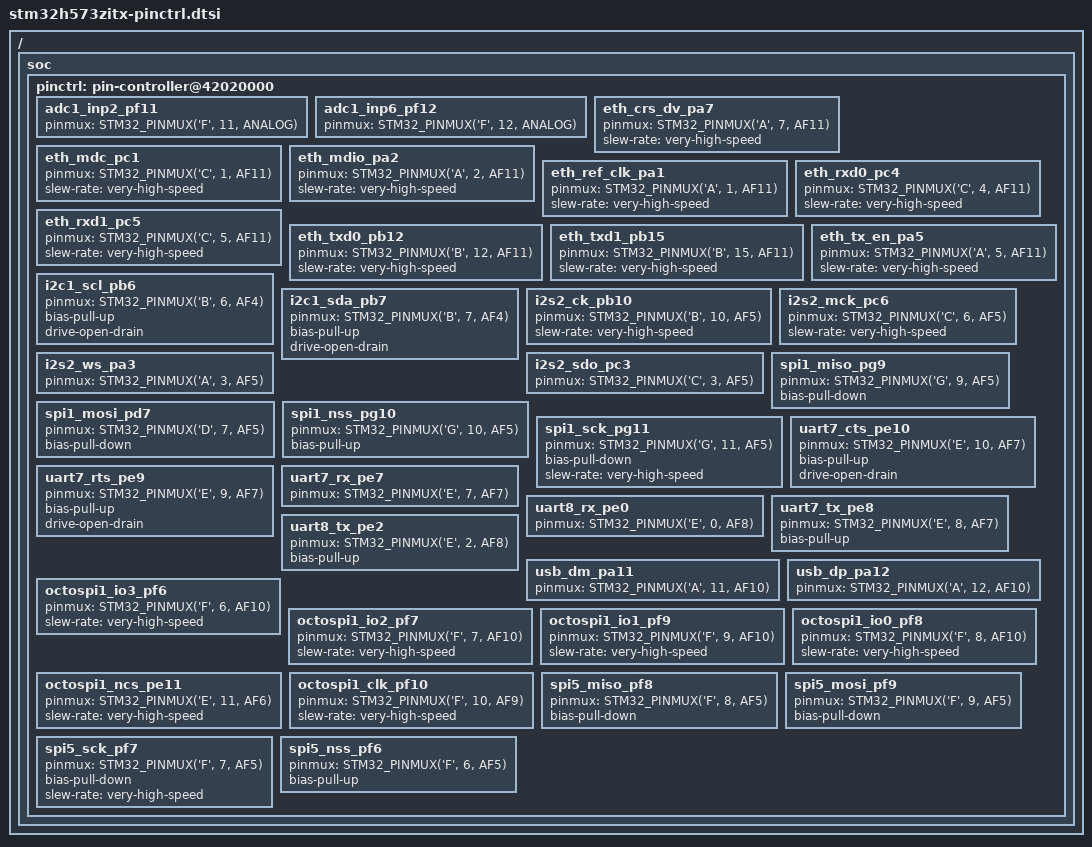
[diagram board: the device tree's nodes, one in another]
#include <zephyr/dt-bindings/pinctrl/stm32-pinctrl.h>

/ {
	soc {
		pinctrl: pin-controller@42020000 {

			/* ADC_IN / ADC_INN / ADC_INP */

			/omit-if-no-ref/ adc1_inp2_pf11: adc1_inp2_pf11 {
				pinmux = <STM32_PINMUX('F', 11, ANALOG)>;
			};

			/omit-if-no-ref/ adc1_inp6_pf12: adc1_inp6_pf12 {
				pinmux = <STM32_PINMUX('F', 12, ANALOG)>;
			};

			/* ETH_CRS_DV */

			/omit-if-no-ref/ eth_crs_dv_pa7: eth_crs_dv_pa7 {
				pinmux = <STM32_PINMUX('A', 7, AF11)>;
				slew-rate = "very-high-speed";
			};

			/* ETH_MDC */

			/omit-if-no-ref/ eth_mdc_pc1: eth_mdc_pc1 {
				pinmux = <STM32_PINMUX('C', 1, AF11)>;
				slew-rate = "very-high-speed";
			};

			/* ETH_MDIO */

			/omit-if-no-ref/ eth_mdio_pa2: eth_mdio_pa2 {
				pinmux = <STM32_PINMUX('A', 2, AF11)>;
				slew-rate = "very-high-speed";
			};


			/* ETH_REF_CLK */

			/omit-if-no-ref/ eth_ref_clk_pa1: eth_ref_clk_pa1 {
				pinmux = <STM32_PINMUX('A', 1, AF11)>;
				slew-rate = "very-high-speed";
			};

			/* ETH_RXD0 */

			/omit-if-no-ref/ eth_rxd0_pc4: eth_rxd0_pc4 {
				pinmux = <STM32_PINMUX('C', 4, AF11)>;
				slew-rate = "very-high-speed";
			};

			/* ETH_RXD1 */

			/omit-if-no-ref/ eth_rxd1_pc5: eth_rxd1_pc5 {
				pinmux = <STM32_PINMUX('C', 5, AF11)>;
				slew-rate = "very-high-speed";
			};

			/* ETH_TXD0 */

			/omit-if-no-ref/ eth_txd0_pb12: eth_txd0_pb12 {
				pinmux = <STM32_PINMUX('B', 12, AF11)>;
				slew-rate = "very-high-speed";
			};

			/* ETH_TXD1 */

			/omit-if-no-ref/ eth_txd1_pb15: eth_txd1_pb15 {
				pinmux = <STM32_PINMUX('B', 15, AF11)>;
				slew-rate = "very-high-speed";
			};

			/* ETH_TX_EN */

			/omit-if-no-ref/ eth_tx_en_pa5: eth_tx_en_pa5 {
				pinmux = <STM32_PINMUX('A', 5, AF11)>;
				slew-rate = "very-high-speed";
			};


			/* I2C_SCL */

			/omit-if-no-ref/ i2c1_scl_pb6: i2c1_scl_pb6 {
				pinmux = <STM32_PINMUX('B', 6, AF4)>;
				bias-pull-up;
				drive-open-drain;
			};

			/* I2C_SDA */

			/omit-if-no-ref/ i2c1_sda_pb7: i2c1_sda_pb7 {
				pinmux = <STM32_PINMUX('B', 7, AF4)>;
				bias-pull-up;
				drive-open-drain;
			};



			/* I2S_CK */
			/omit-if-no-ref/ i2s2_ck_pb10: i2s2_ck_pb10 {
				pinmux = <STM32_PINMUX('B', 10, AF5)>;
				slew-rate = "very-high-speed";
			};

			/* I2S_MCK */

			/omit-if-no-ref/ i2s2_mck_pc6: i2s2_mck_pc6 {
				pinmux = <STM32_PINMUX('C', 6, AF5)>;
				slew-rate = "very-high-speed";
			};


			/* I2S_WS */

			/omit-if-no-ref/ i2s2_ws_pa3: i2s2_ws_pa3 {
				pinmux = <STM32_PINMUX('A', 3, AF5)>;
			};

			/* I2S_SD */

			/omit-if-no-ref/ i2s2_sdo_pc3: i2s2_sdo_pc3 {
				pinmux = <STM32_PINMUX('C', 3, AF5)>;
			};

			/* SPI_MISO */

			/omit-if-no-ref/ spi1_miso_pg9: spi1_miso_pg9 {
				pinmux = <STM32_PINMUX('G', 9, AF5)>;
				bias-pull-down;
			};

			/* SPI_MOSI */

			/omit-if-no-ref/ spi1_mosi_pd7: spi1_mosi_pd7 {
				pinmux = <STM32_PINMUX('D', 7, AF5)>;
				bias-pull-down;
			};

			/* SPI_NSS */

			/omit-if-no-ref/ spi1_nss_pg10: spi1_nss_pg10 {
				pinmux = <STM32_PINMUX('G', 10, AF5)>;
				bias-pull-up;
			};

			/* SPI_SCK */

			/omit-if-no-ref/ spi1_sck_pg11: spi1_sck_pg11 {
				pinmux = <STM32_PINMUX('G', 11, AF5)>;
				bias-pull-down;
				slew-rate = "very-high-speed";
			};

			/* UART_CTS / USART_CTS / LPUART_CTS */

			/omit-if-no-ref/ uart7_cts_pe10: uart7_cts_pe10 {
				pinmux = <STM32_PINMUX('E', 10, AF7)>;
				bias-pull-up;
				drive-open-drain;
			};

			/* UART_RTS / USART_RTS / LPUART_RTS */

			/omit-if-no-ref/ uart7_rts_pe9: uart7_rts_pe9 {
				pinmux = <STM32_PINMUX('E', 9, AF7)>;
				bias-pull-up;
				drive-open-drain;
			};

			/* UART_RX / USART_RX / LPUART_RX */

			/omit-if-no-ref/ uart7_rx_pe7: uart7_rx_pe7 {
				pinmux = <STM32_PINMUX('E', 7, AF7)>;
			};

			/omit-if-no-ref/ uart8_rx_pe0: uart8_rx_pe0 {
				pinmux = <STM32_PINMUX('E', 0, AF8)>;
			};

			/* UART_TX / USART_TX / LPUART_TX */

			/omit-if-no-ref/ uart7_tx_pe8: uart7_tx_pe8 {
				pinmux = <STM32_PINMUX('E', 8, AF7)>;
				bias-pull-up;
			};

			/omit-if-no-ref/ uart8_tx_pe2: uart8_tx_pe2 {
				pinmux = <STM32_PINMUX('E', 2, AF8)>;
				bias-pull-up;
			};

			/* USB */

			/omit-if-no-ref/ usb_dm_pa11: usb_dm_pa11 {
				pinmux = <STM32_PINMUX('A', 11, AF10)>;
			};

			/omit-if-no-ref/ usb_dp_pa12: usb_dp_pa12 {
				pinmux = <STM32_PINMUX('A', 12, AF10)>;
			};

			/* OCTOSPI */

			/omit-if-no-ref/ octospi1_io3_pf6: octospi1_io3_pf6 {
				pinmux = <STM32_PINMUX('F', 6, AF10)>;
				slew-rate = "very-high-speed";
			};

			/omit-if-no-ref/ octospi1_io2_pf7: octospi1_io2_pf7 {
				pinmux = <STM32_PINMUX('F', 7, AF10)>;
				slew-rate = "very-high-speed";
			};

			/omit-if-no-ref/ octospi1_io1_pf9: octospi1_io1_pf9 {
				pinmux = <STM32_PINMUX('F', 9, AF10)>;
				slew-rate = "very-high-speed";
			};

			/omit-if-no-ref/ octospi1_io0_pf8: octospi1_io0_pf8 {
				pinmux = <STM32_PINMUX('F', 8, AF10)>;
				slew-rate = "very-high-speed";
			};

			/omit-if-no-ref/ octospi1_ncs_pe11: octospi1_ncs_pe11 {
				pinmux = <STM32_PINMUX('E', 11, AF6)>;
				slew-rate = "very-high-speed";
			};

			/omit-if-no-ref/ octospi1_clk_pf10: octospi1_clk_pf10 {
				pinmux = <STM32_PINMUX('F', 10, AF9)>;
				slew-rate = "very-high-speed";
			};

			/* SPI */

			/omit-if-no-ref/ spi5_miso_pf8: spi5_miso_pf8 {
				pinmux = <STM32_PINMUX('F', 8, AF5)>;
				bias-pull-down;
			};

			/omit-if-no-ref/ spi5_mosi_pf9: spi5_mosi_pf9 {
				pinmux = <STM32_PINMUX('F', 9, AF5)>;
				bias-pull-down;
			};

			/omit-if-no-ref/ spi5_sck_pf7: spi5_sck_pf7 {
				pinmux = <STM32_PINMUX('F', 7, AF5)>;
				bias-pull-down;
				slew-rate = "very-high-speed";
			};

			/omit-if-no-ref/ spi5_nss_pf6: spi5_nss_pf6 {
				pinmux = <STM32_PINMUX('F', 6, AF5)>;
				bias-pull-up;
			};
		};
	};
};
